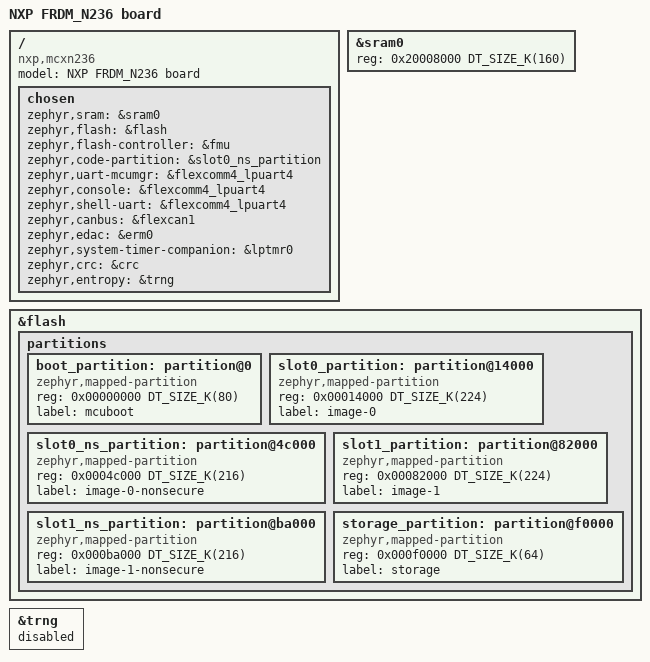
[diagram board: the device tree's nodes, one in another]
/*
 * SPDX-FileCopyrightText: Copyright 2026 NXP
 *
 * SPDX-License-Identifier: Apache-2.0
 */

/dts-v1/;

#include <nxp/mcx/mcxn/nxp_mcxn236_ns.dtsi>
#include "frdm_mcxn236.dtsi"

/ {
	compatible = "nxp,mcxn236", "nxp,mcx";
	model = "NXP FRDM_N236 board";

	chosen {
		zephyr,sram = &sram0;
		zephyr,flash = &flash;
		zephyr,flash-controller = &fmu;
		zephyr,code-partition = &slot0_ns_partition;
		zephyr,uart-mcumgr = &flexcomm4_lpuart4;
		zephyr,console = &flexcomm4_lpuart4;
		zephyr,shell-uart = &flexcomm4_lpuart4;
		zephyr,canbus = &flexcan1;
		zephyr,edac = &erm0;
		zephyr,system-timer-companion = &lptmr0;
		zephyr,crc = &crc;
		zephyr,entropy = &trng;
	};
};

/*
 * frdm_mcxn236.dtsi allocates 192K to sram0. Of that, the first 32K are
 * owned by the secure image; only the remaining 160K are available to this
 * non-secure image.
 */
&sram0 {
	reg = <0x20008000 DT_SIZE_K(160)>;
};

&flash {
	/delete-node/ partitions;

	partitions {
		ranges;
		#address-cells = <1>;
		#size-cells = <1>;

		/*
		 * Partition sizes must be aligned to the flash memory sector size (8 KB).
		 *
		 * This layout is compatible with the requirements given in TF-M
		 * configuration, but does not currently build with TF-M. It might
		 * require adjustment depending on evolutions on TF-M.
		 */
		boot_partition: partition@0 {
			compatible = "zephyr,mapped-partition";
			reg = <0x00000000 DT_SIZE_K(80)>;
			label = "mcuboot";
		};

		/* Secure image - primary */
		slot0_partition: partition@14000 {
			compatible = "zephyr,mapped-partition";
			reg = <0x00014000 DT_SIZE_K(224)>;
			label = "image-0";
		};

		/* Non-secure image - primary */
		slot0_ns_partition: partition@4c000 {
			compatible = "zephyr,mapped-partition";
			reg = <0x0004c000 DT_SIZE_K(216)>;
			label = "image-0-nonsecure";
		};

		/* Secure image - secondary */
		slot1_partition: partition@82000 {
			compatible = "zephyr,mapped-partition";
			reg = <0x00082000 DT_SIZE_K(224)>;
			label = "image-1";
		};

		/* Non-secure image - secondary */
		slot1_ns_partition: partition@ba000 {
			compatible = "zephyr,mapped-partition";
			reg = <0x000ba000 DT_SIZE_K(216)>;
			label = "image-1-nonsecure";
		};

		storage_partition: partition@f0000 {
			compatible = "zephyr,mapped-partition";
			reg = <0x000f0000 DT_SIZE_K(64)>;
			label = "storage";
		};
	};
};

&trng {
	/* Disable TRNG in NS to avoid auto-enabling csprng_available option */
	status = "disabled";
};
